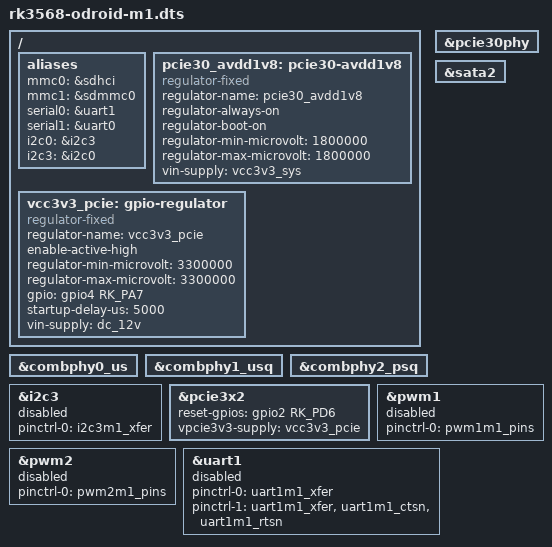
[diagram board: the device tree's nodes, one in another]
// SPDX-License-Identifier: (GPL-2.0+ OR MIT)
/*
 * Copyright (c) 2021 Hardkernel Co., Ltd.
 *
 */

#include "rk3568-odroid-m1.dtsi"
#include "rk3568-android.dtsi"

/ {
	aliases {
		mmc0 = &sdhci;
		mmc1 = &sdmmc0;
		serial0 = &uart1;
		serial1 = &uart0;
		i2c0 = &i2c3;
		i2c3 = &i2c0;
	};

	pcie30_avdd1v8: pcie30-avdd1v8 {
		compatible = "regulator-fixed";
		regulator-name = "pcie30_avdd1v8";
		regulator-always-on;
		regulator-boot-on;
		regulator-min-microvolt = <1800000>;
		regulator-max-microvolt = <1800000>;
		vin-supply = <&vcc3v3_sys>;
	};

	vcc3v3_pcie: gpio-regulator {
		compatible = "regulator-fixed";
		regulator-name = "vcc3v3_pcie";
		enable-active-high;
		regulator-min-microvolt = <3300000>;
		regulator-max-microvolt = <3300000>;
		gpio = <&gpio4 RK_PA7 GPIO_ACTIVE_HIGH>;
		startup-delay-us = <5000>;
		vin-supply = <&dc_12v>;
	};
};

&combphy0_us {
	status = "okay";
};

&combphy1_usq {
	status = "okay";
};

&combphy2_psq {
	status = "okay";
};

&i2c3 {
	status = "disabled";
	pinctrl-names = "default";
	pinctrl-0 = <&i2c3m1_xfer>;
};

&pcie30phy {
	status = "okay";
};

&pcie3x2 {
	reset-gpios = <&gpio2 RK_PD6 GPIO_ACTIVE_HIGH>;
	vpcie3v3-supply = <&vcc3v3_pcie>;
	status = "okay";
};

&sata2 {
	status = "okay";
};

&pwm1 {
	status = "disabled";
	pinctrl-0 = <&pwm1m1_pins>;
};

&pwm2 {
	status = "disabled";
	pinctrl-0 = <&pwm2m1_pins>;
};

&uart1 {
	status = "disabled";
	dma-names = "tx", "rx";
	/* uart1 uart1-with-ctsrts */
	pinctrl-0 = <&uart1m1_xfer>;
	pinctrl-1 = <&uart1m1_xfer &uart1m1_ctsn &uart1m1_rtsn>;
};
